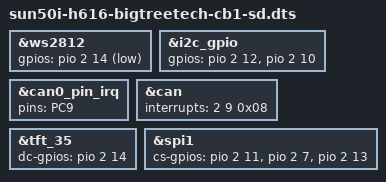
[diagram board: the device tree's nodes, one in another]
// SPDX-License-Identifier: (GPL-2.0+ or MIT)
/*
 * Copyright (C) 2023 Alan.Ma <tech@biqu3d.com>.
 */

/dts-v1/;

#include "sun50i-h616-bigtreetech-cb1.dtsi"

&ws2812 {
	gpios = <&pio 2 14 GPIO_ACTIVE_LOW>; /* PC14 */
};

&i2c_gpio {
	gpios = <&pio 2 12 (GPIO_ACTIVE_HIGH | GPIO_OPEN_DRAIN)>, /* SDA PC12 */
			<&pio 2 10 (GPIO_ACTIVE_HIGH | GPIO_OPEN_DRAIN)>; /* SCL PC10 */
};

&can0_pin_irq {
	pins = "PC9";
};

&can {
	interrupts = <2 9 0x08>; /* PC9 IRQ_TYPE_LEVEL_LOW */
};

&tft_35 {
	dc-gpios  = <&pio 2 14 GPIO_ACTIVE_HIGH>; /* PC14 */
};

&spi1 {
	cs-gpios = <&pio 2 11 GPIO_ACTIVE_HIGH>, /* PC11 */
			   <&pio 2 7 GPIO_ACTIVE_HIGH>, /* PC7 */
			   <&pio 2 13 GPIO_ACTIVE_HIGH>; /* PC13 */
};
